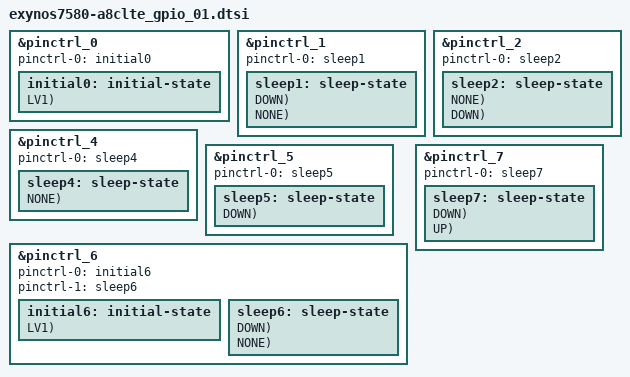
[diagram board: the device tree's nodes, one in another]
/*
 * Copyright (c) 2015 Samsung Electronics Co., Ltd.
 *		http://www.samsung.com
 *
 * This program is free software; you can redistribute it and/or modify
 * it under the terms of the GNU General Public License version 2 as
 * published by the Free Software Foundation.
*/

// Support A8CLTE REV01

#include "exynos_gpio_config_macros.dtsi"

// 0x139B_0000(ALIVE): gpa0~3
&pinctrl_0 {
	pinctrl-names = "default";
	pinctrl-0 = <&initial0>;
	initial0: initial-state {
		PIN_IN(gpa0-0, DOWN, LV1);	/* NC */

		PIN_IN(gpa1-0, DOWN, LV1);	/* NC */
		PIN_IN(gpa1-2, DOWN, LV1);	/* NC */
		PIN_IN(gpa1-5, DOWN, LV1);	/* NC */
		PIN_IN(gpa1-7, DOWN, LV1);	/* NC */

		PIN_IN(gpa3-5, DOWN, LV1);	/* NC */
		PIN_IN(gpa3-6, DOWN, LV1);	/* NC */
	};
};

// 0x110B0000(AUD): gpz0 ~ gpz3
&pinctrl_1 {
	pinctrl-names = "sleep";
	pinctrl-0 = <&sleep1>;
	sleep1: sleep-state {
		PIN_SLP(gpz0-0, INPUT, DOWN);	/* BT_PCM_SYNC */
		PIN_SLP(gpz0-1, INPUT, DOWN);	/* BT_PCM_CLK */
		PIN_SLP(gpz0-2, INPUT, DOWN);	/* BT_PCM_RXD */
		PIN_SLP(gpz0-3, INPUT, DOWN);	/* BT_PCM_TXD */

		PIN_SLP(gpz1-0, OUT0, NONE);	/* BT_UART_TXD */
		PIN_SLP(gpz1-1, INPUT, NONE);	/* BT_UART_RXD */
		PIN_SLP(gpz1-2, INPUT, NONE);	/* BT_UART_CTS */
		PIN_SLP(gpz1-3, OUT1, NONE);	/* BT_UART_RTS */

		PIN_SLP(gpz2-0, INPUT, DOWN);	/* 2MIC_PCM_SYNC */
		PIN_SLP(gpz2-1, INPUT, DOWN);	/* 2MIC_PCM_CLK */
		PIN_SLP(gpz2-2, INPUT, DOWN);	/* 2MIC_AP_PCM_DI */
		PIN_SLP(gpz2-3, INPUT, DOWN);	/* 2MIC_AP_PCM_DO */

		PIN_SLP(gpz3-0, INPUT, DOWN);	/* NC */
		PIN_SLP(gpz3-1, INPUT, DOWN);	/* NC */
		PIN_SLP(gpz3-2, INPUT, DOWN);	/* 2MIC_CLK_24.576MHZ */
		PIN_SLP(gpz3-3, INPUT, DOWN);	/* NC */
	};
};

// 0x138E0000(ESE): gpc0
&pinctrl_2 {
	pinctrl-names = "sleep";
	pinctrl-0 = <&sleep2>;
	sleep2: sleep-state {
		PIN_SLP(gpc0-0, OUT0, NONE);	/* BTP_SPI_CLK */
		PIN_SLP(gpc0-1, OUT0, NONE);	/* BTP_SPI_CS_N */
		PIN_SLP(gpc0-2, INPUT, DOWN);	/* BTP_SPI_MISO */
		PIN_SLP(gpc0-3, OUT0, NONE);	/* BTP_SPI_MOSI */
	};
};

// 0x104E0000(MIF): gpm0
&pinctrl_4 {
	pinctrl-names = "sleep";
	pinctrl-0 = <&sleep4>;
	sleep4: sleep-state {
		PIN_SLP(gpm0-0, INPUT, NONE);	/* PMIC_SDA_1P8 */
		PIN_SLP(gpm0-1, INPUT, NONE);	/* PMIC_SCL_1P8 */
	};
};

// 0x138C0000(NFC): gpc3
&pinctrl_5 {
	pinctrl-names = "sleep";
	pinctrl-0 = <&sleep5>;
	sleep5: sleep-state {
		PIN_SLP(gpc3-0, INPUT, DOWN);	/* NFC_SDA_1P8 *//*NFC NC*/
		PIN_SLP(gpc3-1, INPUT, DOWN);	/* NFC_SCL_1P8 */
		PIN_SLP(gpc3-2, INPUT, DOWN);	/* NFC_EN */
		PIN_SLP(gpc3-3, INPUT, DOWN);	/* NFC_CLK_REQ */
	};
};

// 0x139C0000(TOP): gpb0~2, gpc1~2, gpc5, gpd0~3, gpe0~1, gpf0~2, etc0
&pinctrl_6 {
	pinctrl-names = "default","sleep";
	pinctrl-0 = <&initial6>;
	pinctrl-1 = <&sleep6>;
	initial6: initial-state {
		PIN_IN(gpd0-0, NONE, LV1);	/* HW_REV0 */
		PIN_IN(gpd0-1, NONE, LV1);	/* HW_REV1 */
		PIN_IN(gpd0-2, NONE, LV1);	/* HW_REV2 */
		PIN_IN(gpd0-3, NONE, LV1);	/* HW_REV3 */
	};
	sleep6: sleep-state {
		PIN_SLP(gpb0-0, INPUT, DOWN);	/* AP_UART_RXD */
		PIN_SLP(gpb0-1, INPUT, DOWN);	/* AP_UART_TXD */
		PIN_SLP(gpb0-2, INPUT, NONE);	/* FG_SDA_1P8 */
		PIN_SLP(gpb0-3, INPUT, NONE);	/* FG_SCL_1P8 */
		PIN_SLP(gpb0-4, INPUT, NONE);	/* GPS_RXD */
		PIN_SLP(gpb0-5, OUT0, NONE);	/* GPS_TXD */
		PIN_SLP(gpb0-6, INPUT, NONE);	/* GPS_CTS */
		PIN_SLP(gpb0-7, OUT1, NONE);	/* GPS_RTS */

		PIN_SLP(gpb1-0, INPUT, DOWN);	/* NC */
		PIN_SLP(gpb1-1, INPUT, DOWN);	/* NC */

		PIN_SLP(gpb2-0, INPUT, NONE);	/* PROXY_SCL_1P8 */
		PIN_SLP(gpb2-1, INPUT, NONE);	/* PROXY_SDA_1P8 */
		PIN_SLP(gpb2-2, INPUT, DOWN);	/* NC */
		PIN_SLP(gpb2-3, INPUT, DOWN);	/* NC */
		PIN_SLP(gpb2-4, INPUT, DOWN);	/* NC */
		PIN_SLP(gpb2-5, INPUT, DOWN);	/* NC */
		PIN_SLP(gpb2-6, INPUT, DOWN);	/* NC */
		PIN_SLP(gpb2-7, INPUT, DOWN);	/* NC */

		PIN_SLP(gpc1-0, INPUT, DOWN);	/* NC */
		PIN_SLP(gpc1-1, OUT0, DOWN);	/* MOTOR_PWM */
		PIN_SLP(gpc1-2, INPUT, DOWN);	/* NC */
		PIN_SLP(gpc1-3, INPUT, DOWN);	/* NC */
		PIN_SLP(gpc1-4, INPUT, DOWN);	/* NC */

		PIN_SLP(gpc2-0, INPUT, NONE);	/* SENSOR_SDA_1P8, AMP_SDA_1P8 */
		PIN_SLP(gpc2-1, INPUT, NONE);	/* SENSOR_SCL_1P8, AMP_SCL_1P8 */
		PIN_SLP(gpc2-2, INPUT, NONE);	/* CAM_SDA_1P8 */
		PIN_SLP(gpc2-3, INPUT, NONE);	/* CAM_SCL_1P8 */
		PIN_SLP(gpc2-4, INPUT, NONE);	/* IFPMIC_SDA_1P8 */
		PIN_SLP(gpc2-5, INPUT, NONE);	/* IFPMIC_SCL_1P8 */

		PIN_SLP(gpc5-0, INPUT, DOWN);	/* NC */
		PIN_SLP(gpc5-1, INPUT, DOWN);	/* NC */
		PIN_SLP(gpc5-2, INPUT, DOWN);	/* TOUCH_SDA_1P8 */
		PIN_SLP(gpc5-3, INPUT, DOWN);	/* TOUCH_SCL_1P8 */

		PIN_SLP(gpd0-0, INPUT, NONE);	/* HW_REV0 */
		PIN_SLP(gpd0-1, INPUT, NONE);	/* HW_REV1 */
		PIN_SLP(gpd0-2, INPUT, NONE);	/* HW_REV2 */
		PIN_SLP(gpd0-3, INPUT, NONE);	/* HW_REV3 */
		PIN_SLP(gpd0-4, PREV, NONE);	/* DS_DET */
		PIN_SLP(gpd0-5, OUT0, DOWN);	/* LDO26_EN */
		PIN_SLP(gpd0-6, INPUT, DOWN);	/* CAM_SENSOR_CORE_EN */
		PIN_SLP(gpd0-7, INPUT, DOWN);	/* TE */

		PIN_SLP(gpd1-0, PREV, NONE);	/* WLAN_EN */
		PIN_SLP(gpd1-1, PREV, NONE);	/* BTP_RST_N */
		PIN_SLP(gpd1-2, INPUT, DOWN);	/* NC */
		PIN_SLP(gpd1-3, INPUT, DOWN);	/* MLCD_RST */
		PIN_SLP(gpd1-4, PREV, DOWN);	/* BTP_CHECK */
		PIN_SLP(gpd1-5, PREV, DOWN);	/* BTP_LDO_EN */
		PIN_SLP(gpd1-6, OUT0, NONE);	/* NC */

		PIN_SLP(gpd2-0, INPUT, DOWN);	/* NC */
		PIN_SLP(gpd2-1, INPUT, DOWN);	/* NC */
		PIN_SLP(gpd2-2, INPUT, NONE);	/* UART_CTR */
		PIN_SLP(gpd2-3, INPUT, DOWN);	/* NC */
		PIN_SLP(gpd2-4, INPUT, DOWN);	/* PCD_INT */
		PIN_SLP(gpd2-5, INPUT, DOWN);	/* CHG_EN */
		PIN_SLP(gpd2-6, INPUT, DOWN);	/* GPS_EN */
		PIN_SLP(gpd2-7, INPUT, DOWN);	/* MAIN_MICBIAS_EN */

		PIN_SLP(gpd3-0, INPUT, DOWN);	/* FACTORY_DISCHG */
		PIN_SLP(gpd3-1, INPUT, DOWN);	/* LCD_LDO_EN_1P6 */
		PIN_SLP(gpd3-2, INPUT, DOWN);	/* NC */
		PIN_SLP(gpd3-3, INPUT, NONE);	/* MUIC_SCL_1P8 */
		PIN_SLP(gpd3-4, INPUT, NONE);	/* MUIC_SDA_1P8 */

		PIN_SLP(gpe0-0, INPUT, NONE);	/* NFC_FIRM */
		PIN_SLP(gpe0-1, INPUT, DOWN);	/* CAM_FLASH_TORCH */
		PIN_SLP(gpe0-2, INPUT, DOWN);	/* CAM_FLASH_EN */
		PIN_SLP(gpe0-3, INPUT, DOWN);	/* VTCAM_RST_N */
		PIN_SLP(gpe0-4, INPUT, DOWN);	/* CAM_RST */
		PIN_SLP(gpe0-5, INPUT, DOWN);	/* NC */
		PIN_SLP(gpe0-6, PREV, NONE);	/* CP_RST_N */
		PIN_SLP(gpe0-7, PREV, NONE);	/* MOTOR_EN */

		PIN_SLP(gpe1-0, PREV, NONE);	/* WRSTB_N */
		PIN_SLP(gpe1-1, INPUT, DOWN);	/* NC */
		PIN_SLP(gpe1-2, INPUT, DOWN);	/* NC */
		PIN_SLP(gpe1-3, INPUT, DOWN);	/* NC */
		PIN_SLP(gpe1-4, INPUT, DOWN);	/* NC */

		PIN_SLP(gpf0-0, INPUT, DOWN);	/* CAM_SDA_1P8 */
		PIN_SLP(gpf0-1, INPUT, DOWN);	/* CAM_SCL_1P8 */
		PIN_SLP(gpf0-2, INPUT, DOWN);	/* VTCAM_SDA_1P8 */
		PIN_SLP(gpf0-3, INPUT, DOWN);	/* VTCAM_SCL_1P8 */
		PIN_SLP(gpf0-4, INPUT, DOWN);	/* NC */

		PIN_SLP(gpf1-0, INPUT, DOWN);	/* NC */
		PIN_SLP(gpf1-1, INPUT, DOWN);	/* NC */
		PIN_SLP(gpf1-2, INPUT, DOWN);	/* NC */
		PIN_SLP(gpf1-3, INPUT, DOWN);	/* NC */
		PIN_SLP(gpf1-4, INPUT, DOWN);	/* NC */
		PIN_SLP(gpf1-5, INPUT, DOWN);	/* NC */
		PIN_SLP(gpf1-6, INPUT, DOWN);	/* NC */
		PIN_SLP(gpf1-7, INPUT, DOWN);	/* NC */
	};
};

// 0x138D0000(TOUCH): gpc4
&pinctrl_7 {
	pinctrl-names = "sleep";
	pinctrl-0= <&sleep7>;
	sleep7: sleep-state {
		PIN_SLP(gpc4-0, INPUT, DOWN);	/* TSP_SDA_1P8 */
		PIN_SLP(gpc4-1, INPUT, DOWN);	/* TSP_SCL_1P8 */
		PIN_SLP(gpc4-2, PREV, UP);	/* BT_EN */
	};
};

